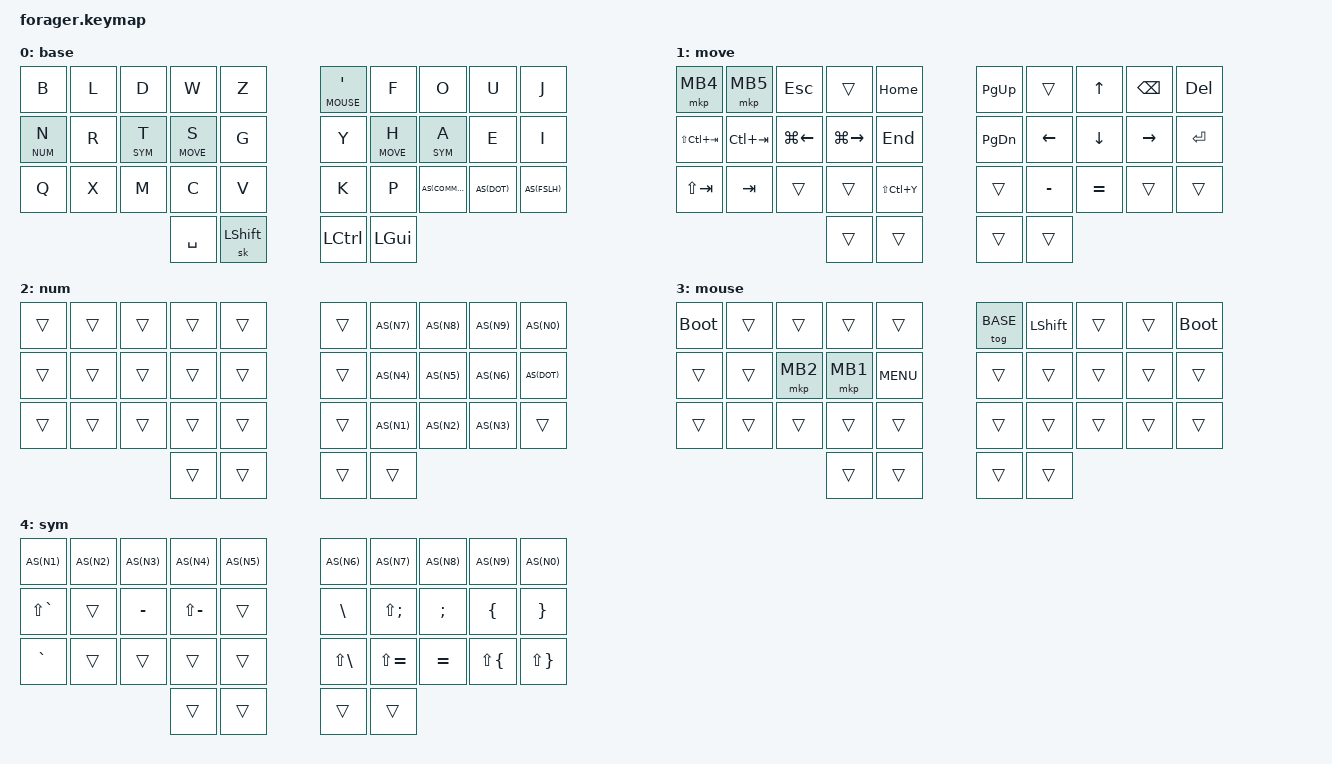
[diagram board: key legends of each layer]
#include <behaviors.dtsi>
#include <dt-bindings/zmk/keys.h>
#include <dt-bindings/zmk/bt.h>
#include <dt-bindings/zmk/outputs.h>

#define BASE  0
#define MOVE  1
#define NUM   2
#define MOUSE 3
#define SYM   4

#define AS(keycode) &as LS(keycode) keycode     // Autoshift Macro
#define MEH LS(LC(LALT))

/ {
    behaviors {
        as: auto_shift {
            compatible = "zmk,behavior-hold-tap";
            #binding-cells = <2>;
            tapping-term-ms = <250>;
            require-prior-idle-ms = <100>;
            flavor = "tap-preferred";
            bindings = <&kp>, <&kp>;
        };
        ht: hold_tap {
            compatible = "zmk,behavior-hold-tap";
            #binding-cells = <2>;
            tapping-term-ms = <200>;
            flavor = "balanced";
            bindings = <&kp>, <&kp>;
        };
        sabk: shift_to_alt_backspace {
            compatible = "zmk,behavior-mod-morph";
            #binding-cells = <0>;
            bindings = <&kp BSPC>, <&kp LA(BSPC)>;
            mods = <(MOD_LSFT|MOD_RSFT)>;
        };
        smart_shift: smart_shift {
            compatible = "zmk,behavior-mod-morph";
            #binding-cells = <0>;
            bindings = <&sk LSHFT>, <&caps_word>;
            mods = <(MOD_LSFT|MOD_RSFT)>;
        };
        sym_bspc: left_thumb_hold_tap {
            compatible = "zmk,behavior-hold-tap";
            #binding-cells = <2>;
            flavor = "tap-preferred";
            tapping-term-ms = <150>;
            quick-tap-ms = <200>;
            bindings = <&mo>, <&sabk>;
        };
        lhm: left_homerow_mods {
            compatible = "zmk,behavior-hold-tap";
            #binding-cells = <2>;
            flavor = "balanced";
            tapping-term-ms = <280>;
            quick-tap-ms = <175>;
            require-prior-idle-ms = <150>;
            bindings = <&kp>, <&kp>;
            hold-trigger-key-positions = <5 6 7 8 9 15 16 17 18 19 25 26 27 28 29 30 31 32 33>;
        };
        rhm: right_homerow_mods {
            compatible = "zmk,behavior-hold-tap";
            #binding-cells = <2>;
            flavor = "balanced";
            tapping-term-ms = <280>;
            quick-tap-ms = <175>;
            require-prior-idle-ms = <150>;
            bindings = <&kp>, <&kp>;
            hold-trigger-key-positions = <0 1 2 3 4 10 11 12 13 14 20 21 22 23 24 30 31 32 33>;
        };
        lt_tp: layer_tap_tap_preferred {
            compatible = "zmk,behavior-hold-tap";
            #binding-cells = <2>;
            flavor = "tap-preferred";
            tapping-term-ms = <150>;
            quick-tap-ms = <200>;
            bindings = <&mo>, <&kp>;
        };
    };

    conditional_layers {
        compatible = "zmk,conditional-layers";
        tri_layer {
            if-layers = <1 2>;
            then-layer = <3>;
        };
    };

    keymap {
        compatible = "zmk,keymap";

        base {
            bindings = <
            &kp B           &kp L           &kp D           &kp W           &kp Z                                           &lt_tp MOUSE SQT  &kp F           &kp O           &kp U           &kp J
            &lt_tp NUM N    &kp R           &lt_tp SYM T    &lt_tp MOVE S   &kp G                                           &kp Y             &lt_tp MOVE H   &lt_tp SYM A    &kp E           &kp I
            &kp Q           &kp X           &kp M           &kp C           &kp V                                           &kp K             &kp P           AS(COMMA)       AS(DOT)         AS(FSLH)
                                                                            &kp SPACE   &sk LSHIFT    &kp LCTRL    &kp LGUI
            >;
        };

        move {
            bindings = <
            &mkp MB4        &mkp MB5        &kp ESC         &trans          &kp HOME                                          &kp PAGE_UP     &trans          &kp UP          &kp BACKSPACE     &kp DELETE
            &kp LS(LC(TAB)) &kp LC(TAB)     &kp LG(LEFT)    &kp LG(RIGHT)   &kp END                                           &kp PAGE_DOWN   &kp LEFT        &kp DOWN        &kp RIGHT         &kp ENTER
            &kp LS(TAB)     &kp TAB         &trans          &trans          &kp LS(LC(Y))                                     &trans          &kp MINUS       &kp EQUAL       &trans            &trans
                                                                            &trans         &trans       &trans          &trans
            >;
        };

        num {
            bindings = <
            &trans          &trans          &trans          &trans        &trans                                          &trans          AS(N7)          AS(N8)          AS(N9)          AS(N0)
            &trans          &trans          &trans          &trans        &trans                                          &trans          AS(N4)          AS(N5)          AS(N6)          AS(DOT)
            &trans          &trans          &trans          &trans        &trans                                          &trans          AS(N1)          AS(N2)          AS(N3)          &trans
                                                                          &trans          &trans          &trans       &trans
            >;
        };

        mouse {
            bindings = <
            &bootloader    &trans          &trans          &trans          &trans                                          &tog BASE       &kp LSHIFT      &trans          &trans          &bootloader
            &trans         &trans          &mkp MB2        &mkp MB1        &kp K_MENU                                      &trans          &trans          &trans          &trans          &trans
            &trans         &trans          &trans          &trans          &trans                                          &trans          &trans          &trans          &trans          &trans
                                                                           &trans          &trans          &trans          &trans
            >;
        };

        sym {
            bindings = <
            AS(N1)          AS(N2)          AS(N3)          AS(N4)          AS(N5)                                          AS(N6)             AS(N7)              AS(N8)          AS(N9)             AS(N0)
            &kp LS(GRAVE)   &trans          &kp MINUS       &kp LS(MINUS)   &trans                                          &kp BACKSLASH      &kp LS(SEMICOLON)   &kp SEMICOLON   &kp LEFT_BRACE     &kp RIGHT_BRACE
            &kp GRAVE       &trans          &trans          &trans          &trans                                          &kp LS(BACKSLASH)  &kp LS(EQUAL)       &kp EQUAL       &kp LS(LEFT_BRACE) &kp LS(RIGHT_BRACE)
                                                                            &trans          &trans          &trans          &trans
            >;
        };
    };
};

&lt {
    // require-prior-idle-ms = <100>;
    tapping-term-ms = <150>;
    quick-tap-ms = <200>;
};

&mt {
    quick-tap-ms = <200>;
};

&sk {
    release-after-ms = <500>;
    quick-release;
};
